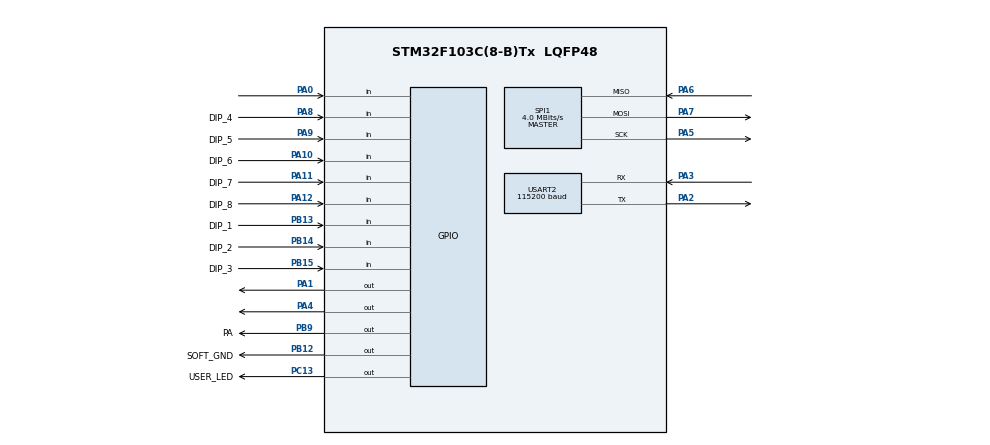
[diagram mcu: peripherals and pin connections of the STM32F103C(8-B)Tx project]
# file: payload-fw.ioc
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Mcu.Family=STM32F1
PA6.Mode=Full_Duplex_Master
SPI1.VirtualType=VM_MASTER
PA10.GPIO_PuPd=GPIO_PULLUP
PB14.GPIO_Label=DIP_2
PB9.GPIO_ModeDefaultOutputPP=GPIO_MODE_OUTPUT_OD
NVIC.TIM1_UP_IRQn=true\:0\:0\:false\:false\:true\:false\:false\:true
PA11.GPIO_PuPd=GPIO_PULLUP
PB13.GPIO_Label=DIP_1
PB13.Signal=GPIO_Input
PB15.Signal=GPIO_Input
ProjectManager.StackSize=0x400
PD1-OSC_OUT.Signal=RCC_OSC_OUT
PA12.Signal=GPIO_Input
SPI1.Direction=SPI_DIRECTION_2LINES
SPI1.CalculateBaudRate=4.0 MBits/s
PB12.GPIO_Label=SOFT_GND
PC14-OSC32_IN.Mode=LSE-External-Oscillator
PC13-TAMPER-RTC.PinState=GPIO_PIN_SET
PA14.Mode=Serial_Wire
VP_SYS_VS_tim1.Mode=TIM1
PA10.GPIO_Label=DIP_6
PA8.Signal=GPIO_Input
PC13-TAMPER-RTC.GPIO_Speed=GPIO_SPEED_FREQ_MEDIUM
VP_FREERTOS_VS_CMSIS_V1.Mode=CMSIS_V1
Mcu.Package=LQFP48
PB9.Signal=GPIO_Output
PB14.GPIO_PuPd=GPIO_PULLUP
PA6.Signal=SPI1_MISO
NVIC.TimeBase=TIM1_UP_IRQn
PB15.GPIO_PuPd=GPIO_PULLUP
USART2.VirtualMode=VM_ASYNC
NVIC.TimeBaseIP=TIM1
PA10.Signal=GPIO_Input
PA12.GPIO_PuPd=GPIO_PULLUP
PA3.Signal=USART2_RX
PA5.Mode=Full_Duplex_Master
RCC.PLLSourceVirtual=RCC_PLLSOURCE_HSE
PC15-OSC32_OUT.Mode=LSE-External-Oscillator
FREERTOS.Tasks01=defaultTask,0,256,StartDefaultTask,Default,NULL,Dynamic,NULL,NULL
PA7.Mode=Full_Duplex_Master
PD1-OSC_OUT.Mode=HSE-External-Oscillator
PB9.GPIO_Label=PA
PA9.GPIO_Label=DIP_5
PC13-TAMPER-RTC.Signal=GPIO_Output
PA11.GPIO_Label=DIP_7
PD0-OSC_IN.Signal=RCC_OSC_IN
PC14-OSC32_IN.Signal=RCC_OSC32_IN
PA9.GPIO_PuPd=GPIO_PULLUP
USART2.BaudRate=115200
PA12.GPIO_Label=DIP_8
PA0-WKUP.Signal=GPIO_Input
PA13.Signal=SYS_JTMS-SWDIO
PA3.Mode=Asynchronous
PA8.GPIO_Label=DIP_4
ProjectManager.TargetToolchain=Other Toolchains (GPDSC)
PA9.Signal=GPIO_Input
RCC.USBFreq_Value=16000000
PC15-OSC32_OUT.Signal=RCC_OSC32_OUT
PA1.Signal=GPIO_Output
PB12.GPIO_Speed=GPIO_SPEED_FREQ_HIGH
PD0-OSC_IN.Mode=HSE-External-Oscillator
PB14.Signal=GPIO_Input
PA5.Signal=SPI1_SCK
board=custom
PC13-TAMPER-RTC.GPIO_Label=USER_LED
PB13.GPIO_PuPd=GPIO_PULLUP
RCC.APB2Freq_Value=8000000
PB15.GPIO_Label=DIP_3
SPI1.Mode=SPI_MODE_MASTER
PA13.Mode=Serial_Wire
Mcu.Name=STM32F103C(8-B)Tx
PA2.Signal=USART2_TX
PA4.Signal=GPIO_Output
PC13-TAMPER-RTC.GPIO_ModeDefaultOutputPP=GPIO_MODE_OUTPUT_OD
PB9.PinState=GPIO_PIN_SET
PA11.Signal=GPIO_Input
PA14.Signal=SYS_JTCK-SWCLK
ProjectManager.HeapSize=0x200
PA8.GPIO_PuPd=GPIO_PULLUP
NVIC.PriorityGroup=NVIC_PRIORITYGROUP_4
PA2.Mode=Asynchronous
RCC.APB1Freq_Value=8000000
PB12.Signal=GPIO_Output
PA7.Signal=SPI1_MOSI

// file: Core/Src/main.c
/* USER CODE BEGIN Header */
/**
  ******************************************************************************
  * @file           : main.c
  * @brief          : Main program body
  ******************************************************************************
  * @attention
  *
  * <h2><center>&copy; Copyright (c) 2020 STMicroelectronics.
  * All rights reserved.</center></h2>
  *
  * This software component is licensed by ST under BSD 3-Clause license,
  * the "License"; You may not use this file except in compliance with the
  * License. You may obtain a copy of the License at:
  *                        opensource.org/licenses/BSD-3-Clause
  *
  ******************************************************************************
  */
/* USER CODE END Header */
#include "main.h"
#include "cmsis_os.h"
#include "spi.h"
#include "usart.h"
#include "gpio.h"

void SystemClock_Config(void);
void MX_FREERTOS_Init(void);
/* USER CODE BEGIN PFP */

int _write(int file, char *ptr, int len) {
	int i;
	HAL_UART_Transmit(&huart2, (uint8_t*) ptr, len, 50);
	for (i = 0; i < len; i++) {
		ITM_SendChar(*ptr++);
	}
	return len;
}

/* USER CODE END PFP */

int main(void)
{

  /* MCU Configuration--------------------------------------------------------*/

  /* Reset of all peripherals, Initializes the Flash interface and the Systick. */
  HAL_Init();

  /* Configure the system clock */
  SystemClock_Config();

  /* Initialize all configured peripherals */
  MX_GPIO_Init();
  MX_SPI1_Init();
  MX_USART2_UART_Init();
  /* USER CODE BEGIN 2 */
  printf("\n\r\n\rStarting RTOS\r\n");
  /* USER CODE END 2 */

  /* Call init function for freertos objects (in freertos.c) */
  MX_FREERTOS_Init();
  /* Start scheduler */
  osKernelStart();

  /* We should never get here as control is now taken by the scheduler */
  /* Infinite loop */
  while (1)
  {

  }
}

void SystemClock_Config(void)
{
  RCC_OscInitTypeDef RCC_OscInitStruct = {0};
  RCC_ClkInitTypeDef RCC_ClkInitStruct = {0};

  /** Initializes the RCC Oscillators according to the specified parameters
  * in the RCC_OscInitTypeDef structure.
  */
  RCC_OscInitStruct.OscillatorType = RCC_OSCILLATORTYPE_HSI;
  RCC_OscInitStruct.HSIState = RCC_HSI_ON;
  RCC_OscInitStruct.HSICalibrationValue = RCC_HSICALIBRATION_DEFAULT;
  RCC_OscInitStruct.PLL.PLLState = RCC_PLL_NONE;
  if (HAL_RCC_OscConfig(&RCC_OscInitStruct) != HAL_OK)
  {
    Error_Handler();
  }
  /** Initializes the CPU, AHB and APB buses clocks
  */
  RCC_ClkInitStruct.ClockType = RCC_CLOCKTYPE_HCLK|RCC_CLOCKTYPE_SYSCLK
                              |RCC_CLOCKTYPE_PCLK1|RCC_CLOCKTYPE_PCLK2;
  RCC_ClkInitStruct.SYSCLKSource = RCC_SYSCLKSOURCE_HSI;
  RCC_ClkInitStruct.AHBCLKDivider = RCC_SYSCLK_DIV1;
  RCC_ClkInitStruct.APB1CLKDivider = RCC_HCLK_DIV1;
  RCC_ClkInitStruct.APB2CLKDivider = RCC_HCLK_DIV1;

  if (HAL_RCC_ClockConfig(&RCC_ClkInitStruct, FLASH_LATENCY_0) != HAL_OK)
  {
    Error_Handler();
  }
}

void HAL_TIM_PeriodElapsedCallback(TIM_HandleTypeDef *htim)
{
  if (htim->Instance == TIM1) {
    HAL_IncTick();
  }
}

void Error_Handler(void)
{
}

/************************ (C) COPYRIGHT STMicroelectronics *****END OF FILE****/

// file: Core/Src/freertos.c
/* USER CODE BEGIN Header */
/**
  ******************************************************************************
  * File Name          : freertos.c
  * Description        : Code for freertos applications
  ******************************************************************************
  * @attention
  *
  * <h2><center>&copy; Copyright (c) 2020 STMicroelectronics.
  * All rights reserved.</center></h2>
  *
  * This software component is licensed by ST under Ultimate Liberty license
  * SLA0044, the "License"; You may not use this file except in compliance with
  * the License. You may obtain a copy of the License at:
  *                             www.st.com/SLA0044
  *
  ******************************************************************************
  */
/* USER CODE END Header */

#include "FreeRTOS.h"
#include "task.h"
#include "main.h"
#include "cmsis_os.h"

osThreadId defaultTaskHandle;

/* USER CODE BEGIN FunctionPrototypes */
void app();
void loraTest();
/* USER CODE END FunctionPrototypes */

void StartDefaultTask(void const * argument);

void MX_FREERTOS_Init(void); /* (MISRA C 2004 rule 8.1) */

/* GetIdleTaskMemory prototype (linked to static allocation support) */
void vApplicationGetIdleTaskMemory( StaticTask_t **ppxIdleTaskTCBBuffer, StackType_t **ppxIdleTaskStackBuffer, uint32_t *pulIdleTaskStackSize );

/* USER CODE BEGIN GET_IDLE_TASK_MEMORY */
static StaticTask_t xIdleTaskTCBBuffer;
static StackType_t xIdleStack[configMINIMAL_STACK_SIZE];

void vApplicationGetIdleTaskMemory( StaticTask_t **ppxIdleTaskTCBBuffer, StackType_t **ppxIdleTaskStackBuffer, uint32_t *pulIdleTaskStackSize )
{
  *ppxIdleTaskTCBBuffer = &xIdleTaskTCBBuffer;
  *ppxIdleTaskStackBuffer = &xIdleStack[0];
  *pulIdleTaskStackSize = configMINIMAL_STACK_SIZE;
  /* place for user code */
}
/* USER CODE END GET_IDLE_TASK_MEMORY */

void MX_FREERTOS_Init(void) {

  /* Create the thread(s) */
  /* definition and creation of defaultTask */
  osThreadDef(defaultTask, StartDefaultTask, osPriorityNormal, 0, 256);
  defaultTaskHandle = osThreadCreate(osThread(defaultTask), NULL);

}

void StartDefaultTask(void const * argument)
{
  /* USER CODE BEGIN StartDefaultTask */
  //app();
  loraTest();

  /* Infinite loop */
  for(;;)
  {
    osDelay(1);
  }
  /* USER CODE END StartDefaultTask */
}

/************************ (C) COPYRIGHT STMicroelectronics *****END OF FILE****/
